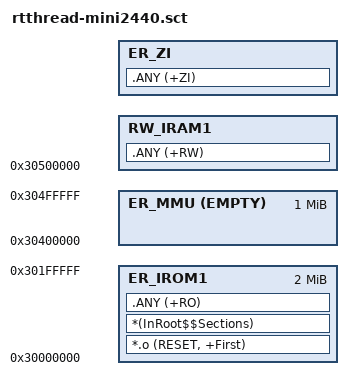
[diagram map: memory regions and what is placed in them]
LR_IROM1 0x30000000 0x1000000 {
  ER_IROM1 0x30000000 0x00200000  {  ; load address = execution address
   *.o (RESET, +First)
   *(InRoot$$Sections)
   .ANY (+RO)
  }

  ER_MMU 0x30400000 EMPTY 0x00100000 {
  }

  RW_IRAM1 0x30500000 {  ; RW data
   .ANY (+RW)
  }

  ER_ZI +0 { ; ZI data
   .ANY (+ZI)
  }
}
